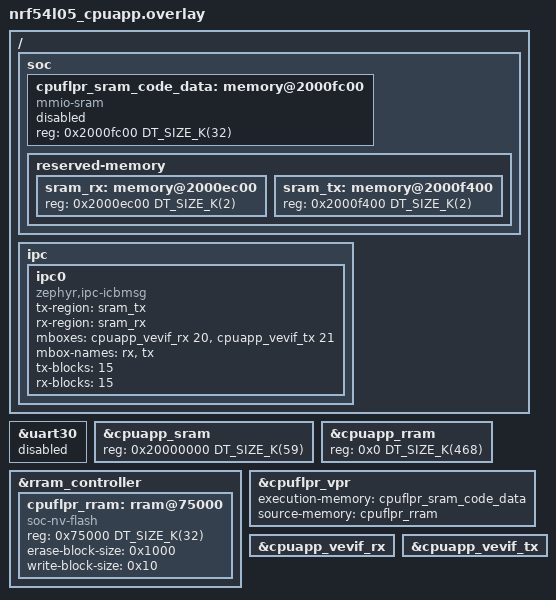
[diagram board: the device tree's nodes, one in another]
/*
 * Copyright (c) 2026 Nordic Semiconductor
 * SPDX-License-Identifier: Apache-2.0
 */

/ {
	soc {
		cpuflpr_sram_code_data: memory@2000fc00 {
			compatible = "mmio-sram";
			reg = <0x2000fc00 DT_SIZE_K(32)>;
			ranges = <0x0 0x2000fc00 DT_SIZE_K(32)>;
			status = "reserved";
			#address-cells = <1>;
			#size-cells = <1>;
		};

		reserved-memory {
			#address-cells = <1>;
			#size-cells = <1>;

			sram_rx: memory@2000ec00 {
				reg = <0x2000ec00 DT_SIZE_K(2)>;
			};

			sram_tx: memory@2000f400 {
				reg = <0x2000f400 DT_SIZE_K(2)>;
			};
		};
	};

	ipc {
		ipc0: ipc0 {
			compatible = "zephyr,ipc-icbmsg";
			tx-region = <&sram_tx>;
			rx-region = <&sram_rx>;
			mboxes = <&cpuapp_vevif_rx 20>, <&cpuapp_vevif_tx 21>;
			mbox-names = "rx", "tx";
			tx-blocks = <15>;
			rx-blocks = <15>;
			status = "okay";
		};
	};
};

&uart30 {
	status = "reserved";
};

&cpuapp_sram {
	reg = <0x20000000 DT_SIZE_K(59)>;
	ranges = <0x0 0x20000000 DT_SIZE_K(59)>;
};

&cpuapp_rram {
	reg = <0x0 DT_SIZE_K(468)>;
	ranges = <0x0 0x0 DT_SIZE_K(468)>;

	/delete-node/ partitions;
};

&rram_controller {
	cpuflpr_rram: rram@75000 {
		compatible = "soc-nv-flash";
		reg = <0x75000 DT_SIZE_K(32)>;
		ranges = <0x0 0x75000 DT_SIZE_K(32)>;
		erase-block-size = <0x1000>;
		write-block-size = <0x10>;
		#address-cells = <1>;
		#size-cells = <1>;
	};
};

&cpuflpr_vpr {
	execution-memory = <&cpuflpr_sram_code_data>;
	source-memory = <&cpuflpr_rram>;
};

&cpuapp_vevif_rx {
	status = "okay";
};

&cpuapp_vevif_tx {
	status = "okay";
};

#define WITH_FLPR_PARTITIONS
#include <vendor/nordic/nrf54l05_cpuapp_partition.dtsi>
